# JTAG register map
Vendor: litex
Registers are 32-bit, read-write, reset 0x0 unless marked. A register's access mark holds for its fields unless they carry their own. Offsets are from the block's base; [hi:lo] are bit positions; {n}, {i} and the like mark numbered series.

## SHA2
Base 0xF0019000
{0x0+4i} KEY{i} (i=0..7) — secret key word {i}
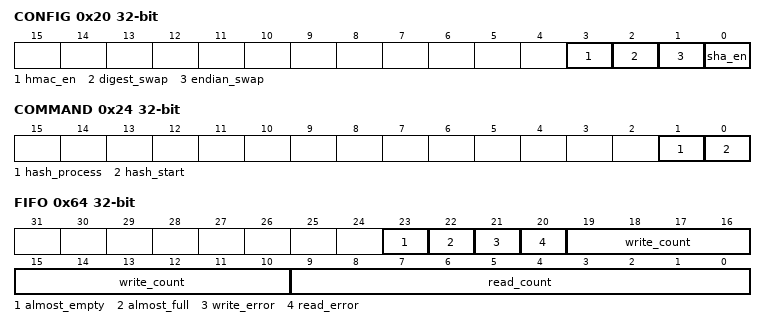
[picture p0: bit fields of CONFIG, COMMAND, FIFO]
0x20 CONFIG — Configuration register for the HMAC block
  [3] hmac_en — Enable the HMAC core
  [2] digest_swap — Swap the endianness on the output digest
  [1] endian_swap — Swap the endianness on the input data
  [0] sha_en — Enable the SHA256 core
0x24 COMMAND — Command register for the HMAC block
  [1] hash_process — Writing a 1 digests the hash data
  [0] hash_start — Writing a 1 indicates the beginning of hash data
0x28 WIPE — wipe the secret key using the written value. Wipe happens upon write.
{0x2C+4i} DIGEST{i} ro (i=0..7) — digest word {i}
0x4C MSG_LENGTH1 ro — Bits 32-63 of `SHA2_MSG_LENGTH`. Length of digested message, in bits
  [31:0] msg_length
0x50 MSG_LENGTH0 ro — Bits 0-31 of `SHA2_MSG_LENGTH`.
  [31:0] msg_length
0x54 ERROR_CODE ro
0x58 EV_STATUS
  [3:0] status
0x5C EV_PENDING
  [3:0] pending
0x60 EV_ENABLE
  [3:0] enable
0x64 FIFO ro — FIFO status
  [23] almost_empty
  [22] almost_full
  [21] write_error — write error occurred
  [20] read_error — read error occurred
  [19:10] write_count — write pointer
  [9:0] read_count — read pointer

## SHA512
Base 0xF001A000
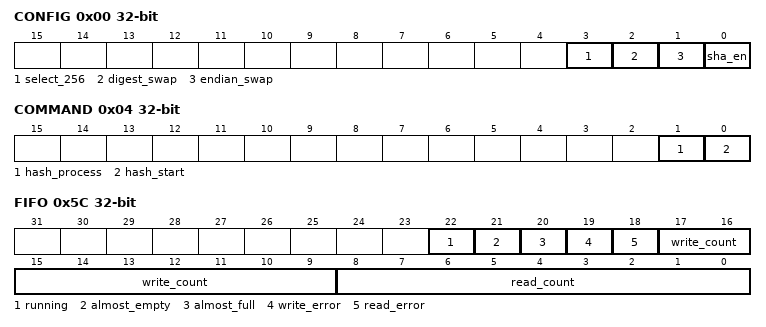
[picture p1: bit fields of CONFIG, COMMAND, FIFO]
0x00 CONFIG — Configuration register for the HMAC block
  [3] select_256 — Select SHA512/256 IV constants when set to `1`
  [2] digest_swap — Swap the endianness on the output digest
  [1] endian_swap — Swap the endianness on the input data
  [0] sha_en — Enable the SHA512 core
0x04 COMMAND — Command register for the HMAC block
  [1] hash_process — Writing a 1 digests the hash data
  [0] hash_start — Writing a 1 indicates the beginning of hash data
0x08 DIGEST01 ro — Bits 32-63 of `SHA512_DIGEST0`. digest word 0
  [31:0] digest0
0x0C DIGEST00 ro — Bits 0-31 of `SHA512_DIGEST0`.
  [31:0] digest0
0x10 DIGEST11 ro — Bits 32-63 of `SHA512_DIGEST1`. digest word 1
  [31:0] digest1
0x14 DIGEST10 ro — Bits 0-31 of `SHA512_DIGEST1`.
  [31:0] digest1
0x18 DIGEST21 ro — Bits 32-63 of `SHA512_DIGEST2`. digest word 2
  [31:0] digest2
0x1C DIGEST20 ro — Bits 0-31 of `SHA512_DIGEST2`.
  [31:0] digest2
0x20 DIGEST31 ro — Bits 32-63 of `SHA512_DIGEST3`. digest word 3
  [31:0] digest3
0x24 DIGEST30 ro — Bits 0-31 of `SHA512_DIGEST3`.
  [31:0] digest3
0x28 DIGEST41 ro — Bits 32-63 of `SHA512_DIGEST4`. digest word 4
  [31:0] digest4
0x2C DIGEST40 ro — Bits 0-31 of `SHA512_DIGEST4`.
  [31:0] digest4
0x30 DIGEST51 ro — Bits 32-63 of `SHA512_DIGEST5`. digest word 5
  [31:0] digest5
0x34 DIGEST50 ro — Bits 0-31 of `SHA512_DIGEST5`.
  [31:0] digest5
0x38 DIGEST61 ro — Bits 32-63 of `SHA512_DIGEST6`. digest word 6
  [31:0] digest6
0x3C DIGEST60 ro — Bits 0-31 of `SHA512_DIGEST6`.
  [31:0] digest6
0x40 DIGEST71 ro — Bits 32-63 of `SHA512_DIGEST7`. digest word 7
  [31:0] digest7
0x44 DIGEST70 ro — Bits 0-31 of `SHA512_DIGEST7`.
  [31:0] digest7
0x48 MSG_LENGTH1 ro — Bits 32-63 of `SHA512_MSG_LENGTH`. Bottom 64 bits of length of digested message, in bits
  [31:0] msg_length
0x4C MSG_LENGTH0 ro — Bits 0-31 of `SHA512_MSG_LENGTH`.
  [31:0] msg_length
0x50 EV_STATUS
  [2:0] status
0x54 EV_PENDING
  [2:0] pending
0x58 EV_ENABLE
  [2:0] enable
0x5C FIFO ro — FIFO status
  [22] running — hash engine is running and controls are locked out
  [21] almost_empty
  [20] almost_full
  [19] write_error — write error occurred
  [18] read_error — read error occurred
  [17:9] write_count — write pointer
  [8:0] read_count — read pointer

## ENGINE
Base 0xF001B000
0x00 WINDOW
  [3:0] window — Selects the current register window to use
0x04 MPSTART
  [9:0] mpstart — Where to start execution
0x08 MPLEN
  [9:0] mplen — Length of the current microcode program. Thus valid code must be in the range of [mpstart, mpstart + mplen]
0x0C CONTROL
  [0] go — Writing to this puts the engine in `run` mode, and it will execute mplen microcode instructions starting at mpstart
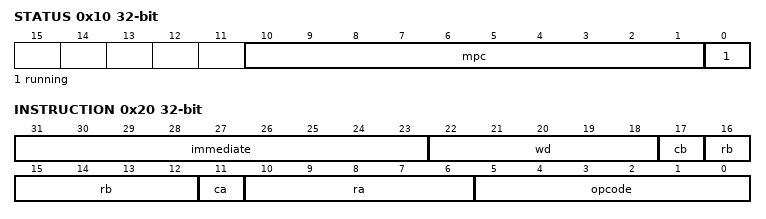
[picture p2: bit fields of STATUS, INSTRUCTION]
0x10 STATUS
  [10:1] mpc — Current location of the microcode program counter. Mostly for debug.
  [0] running — When set, the microcode engine is running. All wishbone access to RF and microcode memory areas will stall until this bit is clear
0x14 EV_STATUS
  [1:0] status
0x18 EV_PENDING
  [1:0] pending
0x1C EV_ENABLE
  [1:0] enable
0x20 INSTRUCTION ro — Current instruction being executed by the engine. The format of this register exactly reflects the binary layout of an Engine instruction.
  [31:23] immediate — Used by jumps to load the next PC value
  [22:18] wd — write register
  [17] cb — set to substitute constant table value for B
  [16:12] rb — operand B read register
  [11] ca — set to substitute constant table value for A
  [10:6] ra — operand A read register
  [5:0] opcode — opcode to be executed

## JTAG
Base 0xF001C000
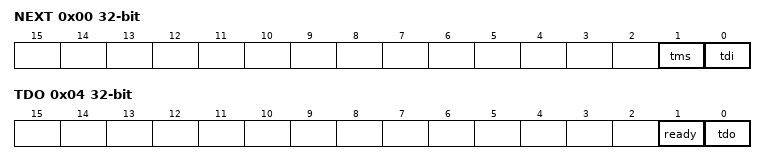
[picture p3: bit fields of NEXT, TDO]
0x00 NEXT — Next state for TDI/TMS; writing automatically clocks TCK
  [1] tms — TMS pin value
  [0] tdi — TDI pin value
0x04 TDO ro — TDO resulting from previous cycle
  [1] ready — JTAG machine is ready for a new cycle; also indicates TDO is valid
  [0] tdo — TDO pin value
